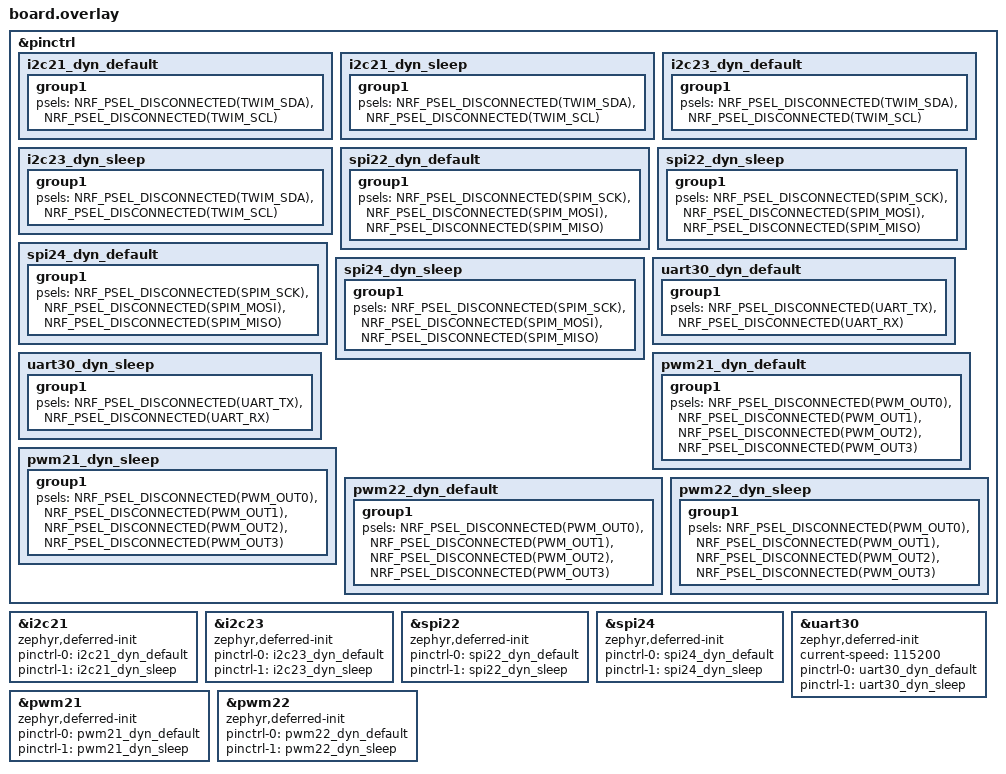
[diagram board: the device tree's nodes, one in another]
// nRF54LM20 DK has USB. Include the main app overlay for USB CDC ACM console and data.
#include "../../../app.overlay"

// Enable every free serial peripheral instance so CircuitPython can mux it to
// arbitrary pins at runtime. Each instance is enabled in one mode because the
// i2c/spi/uart nodes of an instance are the same peripheral (enforced by
// zephyr/soc/nordic/validate_enabled_instances.c). All signals are
// disconnected and the devices are marked zephyr,deferred-init so nothing is
// claimed at boot; iobroker initializes and routes a device when a busio
// object is constructed and de-initializes it on release.
//
// Instance 20 is left alone: uart20 is the console (main UART) and i2c20/spi20
// share that same peripheral, so they must not be enabled. Instance 00 is
// owned by spi00 and the MX25R64 SPI flash, so uart00 must not be enabled.

&pinctrl {
	i2c21_dyn_default: i2c21_dyn_default {
		group1 {
			psels = <NRF_PSEL_DISCONNECTED(TWIM_SDA)>,
				<NRF_PSEL_DISCONNECTED(TWIM_SCL)>;
		};
	};

	i2c21_dyn_sleep: i2c21_dyn_sleep {
		group1 {
			psels = <NRF_PSEL_DISCONNECTED(TWIM_SDA)>,
				<NRF_PSEL_DISCONNECTED(TWIM_SCL)>;
		};
	};

	i2c23_dyn_default: i2c23_dyn_default {
		group1 {
			psels = <NRF_PSEL_DISCONNECTED(TWIM_SDA)>,
				<NRF_PSEL_DISCONNECTED(TWIM_SCL)>;
		};
	};

	i2c23_dyn_sleep: i2c23_dyn_sleep {
		group1 {
			psels = <NRF_PSEL_DISCONNECTED(TWIM_SDA)>,
				<NRF_PSEL_DISCONNECTED(TWIM_SCL)>;
		};
	};

	spi22_dyn_default: spi22_dyn_default {
		group1 {
			psels = <NRF_PSEL_DISCONNECTED(SPIM_SCK)>,
				<NRF_PSEL_DISCONNECTED(SPIM_MOSI)>,
				<NRF_PSEL_DISCONNECTED(SPIM_MISO)>;
		};
	};

	spi22_dyn_sleep: spi22_dyn_sleep {
		group1 {
			psels = <NRF_PSEL_DISCONNECTED(SPIM_SCK)>,
				<NRF_PSEL_DISCONNECTED(SPIM_MOSI)>,
				<NRF_PSEL_DISCONNECTED(SPIM_MISO)>;
		};
	};

	spi24_dyn_default: spi24_dyn_default {
		group1 {
			psels = <NRF_PSEL_DISCONNECTED(SPIM_SCK)>,
				<NRF_PSEL_DISCONNECTED(SPIM_MOSI)>,
				<NRF_PSEL_DISCONNECTED(SPIM_MISO)>;
		};
	};

	spi24_dyn_sleep: spi24_dyn_sleep {
		group1 {
			psels = <NRF_PSEL_DISCONNECTED(SPIM_SCK)>,
				<NRF_PSEL_DISCONNECTED(SPIM_MOSI)>,
				<NRF_PSEL_DISCONNECTED(SPIM_MISO)>;
		};
	};

	uart30_dyn_default: uart30_dyn_default {
		group1 {
			psels = <NRF_PSEL_DISCONNECTED(UART_TX)>,
				<NRF_PSEL_DISCONNECTED(UART_RX)>;
		};
	};

	uart30_dyn_sleep: uart30_dyn_sleep {
		group1 {
			psels = <NRF_PSEL_DISCONNECTED(UART_TX)>,
				<NRF_PSEL_DISCONNECTED(UART_RX)>;
		};
	};

	pwm21_dyn_default: pwm21_dyn_default {
		group1 {
			psels = <NRF_PSEL_DISCONNECTED(PWM_OUT0)>,
				<NRF_PSEL_DISCONNECTED(PWM_OUT1)>,
				<NRF_PSEL_DISCONNECTED(PWM_OUT2)>,
				<NRF_PSEL_DISCONNECTED(PWM_OUT3)>;
		};
	};

	pwm21_dyn_sleep: pwm21_dyn_sleep {
		group1 {
			psels = <NRF_PSEL_DISCONNECTED(PWM_OUT0)>,
				<NRF_PSEL_DISCONNECTED(PWM_OUT1)>,
				<NRF_PSEL_DISCONNECTED(PWM_OUT2)>,
				<NRF_PSEL_DISCONNECTED(PWM_OUT3)>;
		};
	};

	pwm22_dyn_default: pwm22_dyn_default {
		group1 {
			psels = <NRF_PSEL_DISCONNECTED(PWM_OUT0)>,
				<NRF_PSEL_DISCONNECTED(PWM_OUT1)>,
				<NRF_PSEL_DISCONNECTED(PWM_OUT2)>,
				<NRF_PSEL_DISCONNECTED(PWM_OUT3)>;
		};
	};

	pwm22_dyn_sleep: pwm22_dyn_sleep {
		group1 {
			psels = <NRF_PSEL_DISCONNECTED(PWM_OUT0)>,
				<NRF_PSEL_DISCONNECTED(PWM_OUT1)>,
				<NRF_PSEL_DISCONNECTED(PWM_OUT2)>,
				<NRF_PSEL_DISCONNECTED(PWM_OUT3)>;
		};
	};
};

&i2c21 {
	status = "okay";
	zephyr,deferred-init;
	pinctrl-0 = <&i2c21_dyn_default>;
	pinctrl-1 = <&i2c21_dyn_sleep>;
	pinctrl-names = "default", "sleep";
};

&i2c23 {
	status = "okay";
	zephyr,deferred-init;
	pinctrl-0 = <&i2c23_dyn_default>;
	pinctrl-1 = <&i2c23_dyn_sleep>;
	pinctrl-names = "default", "sleep";
};

&spi22 {
	status = "okay";
	zephyr,deferred-init;
	pinctrl-0 = <&spi22_dyn_default>;
	pinctrl-1 = <&spi22_dyn_sleep>;
	pinctrl-names = "default", "sleep";
};

&spi24 {
	status = "okay";
	zephyr,deferred-init;
	pinctrl-0 = <&spi24_dyn_default>;
	pinctrl-1 = <&spi24_dyn_sleep>;
	pinctrl-names = "default", "sleep";
};

&uart30 {
	status = "okay";
	zephyr,deferred-init;
	current-speed = <115200>;
	pinctrl-0 = <&uart30_dyn_default>;
	pinctrl-1 = <&uart30_dyn_sleep>;
	pinctrl-names = "default", "sleep";
};

// PWM instances 21 and 22, same scheme: all four outputs disconnected and
// deferred init, so iobroker can hand an instance to neopixel_write and
// pwmio and route its outputs at runtime. Instance 20 is left as the board
// defines it: enabled with fixed pins for the PWM LED. On this SoC the "2x"
// instances can only drive P1 and P3 pads (see the iobroker README).

&pwm21 {
	status = "okay";
	zephyr,deferred-init;
	pinctrl-0 = <&pwm21_dyn_default>;
	pinctrl-1 = <&pwm21_dyn_sleep>;
	pinctrl-names = "default", "sleep";
};

&pwm22 {
	status = "okay";
	zephyr,deferred-init;
	pinctrl-0 = <&pwm22_dyn_default>;
	pinctrl-1 = <&pwm22_dyn_sleep>;
	pinctrl-names = "default", "sleep";
};
